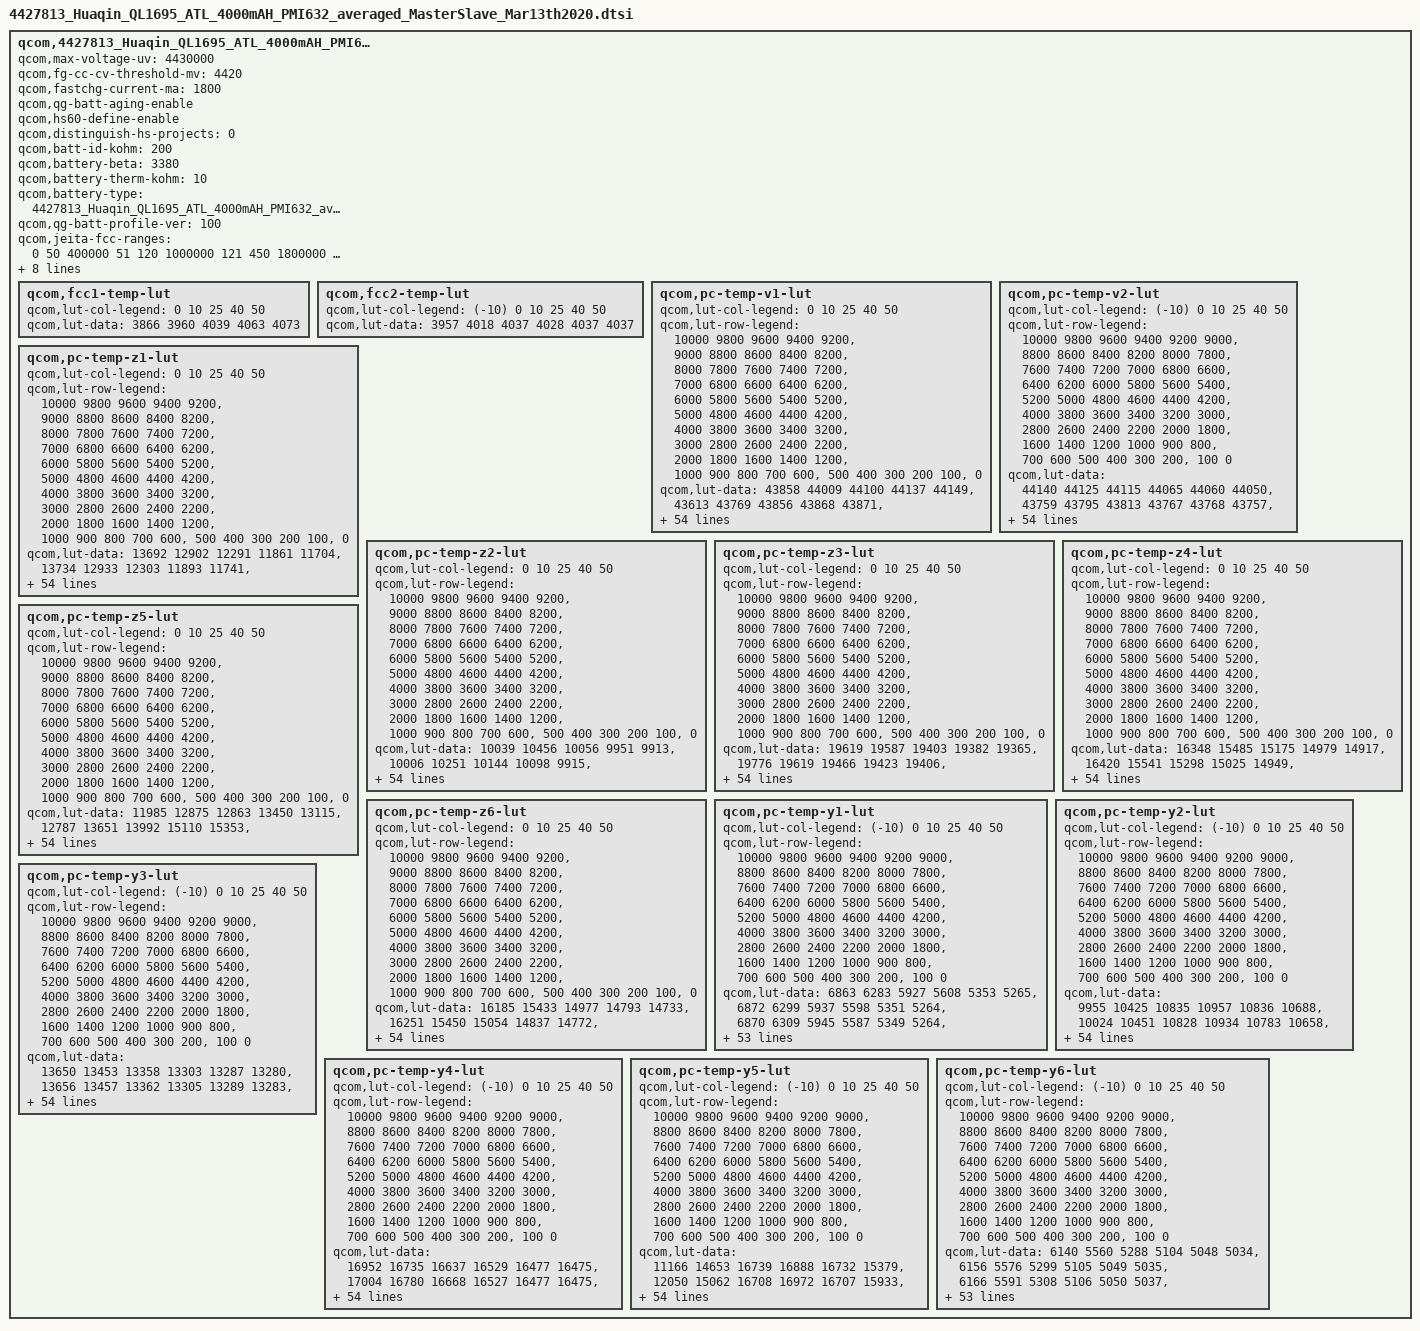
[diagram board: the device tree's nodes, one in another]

qcom,4427813_Huaqin_QL1695_ATL_4000mAH_PMI632 {
    /* 4427813_Huaqin_QL1695_ATL_4000mAH_PMI632_averaged_MasterSlave_Mar13th2020 */
    qcom,max-voltage-uv = <4430000>;
	qcom,fg-cc-cv-threshold-mv = <4420>;
	/* HS60 add for ZQL1693-60 Encrease FCC to 1800mA to trigger TA(5V/1.55A) more ICL by gaochao at 2019/11/05 start */
	qcom,fastchg-current-ma = <1800>;
	/* HS60 add for ZQL1693-60 Encrease FCC to 1800mA to trigger TA(5V/1.55A) more ICL by gaochao at 2019/11/05 end */
	/* HS60 add for SR-ZQL1695-01-357 Import battery aging by gaochao at 2019/08/29 start */
	qcom,qg-batt-aging-enable;
	/* HS60 add for SR-ZQL1695-01-357 Import battery aging by gaochao at 2019/08/29 end */
	/* HS70 add for HS70-135 Distinguish HS60 and HS70 charging by gaochao at 2019/10/03 start */
	qcom,hs60-define-enable;
	/* HS70 add for HS70-135 Distinguish HS60 and HS70 charging by gaochao at 2019/10/03 end */
	/* HS50 add for SR-QL3095-01-67 Distinguish HS60, HS70 and HS50 charging by wenyaqi at 2020/8/3 start */
	qcom,distinguish-hs-projects = <0>;
	/* HS50 add for SR-QL3095-01-67 Distinguish HS60, HS70 and HS50 charging by wenyaqi at 2020/8/3 end */
	qcom,batt-id-kohm = <200>;
	qcom,battery-beta = <3380>;
    qcom,battery-therm-kohm = <10>;
    qcom,battery-type = "4427813_Huaqin_QL1695_ATL_4000mAH_PMI632_averaged_MasterSlave_Mar13th2020";
    qcom,qg-batt-profile-ver = <100>;
	/*HS60 add for ZQL1693-50 by wangzikang at 2019/09/26 start*/
	/*HS60 add for ZQL1693-58 by wangzikang at 2019/10/18 start*/
	/* HS60 add for ZQL1693-60 Encrease FCC to 1800mA to trigger TA(5V/1.55A) more ICL by gaochao at 2019/11/05 start */
	qcom,jeita-fcc-ranges = <0   50  400000
				 51   120   1000000
				 121 450  1800000
				 451 500  1800000>;
	/* HS60 add for ZQL1693-60 Encrease FCC to 1800mA to trigger TA(5V/1.55A) more ICL by gaochao at 2019/11/05 end */
	/*HS60 add for ZQL1693-58 by wangzikang at 2019/10/18 end*/
	qcom,jeita-fv-ranges =  <0   50  4430000
				 51   120  4430000
				 121 450  4430000
				 451 500  4200000>;
	/*HS60 add for ZQL1693-50 by wangzikang at 2019/09/26 end*/
	/* HS60 add for SR-ZQL1695-01-357 Import battery aging by gaochao at 2019/08/29 start */
	qcom,vfloat-ranges = <0 299 4430000
	                      300 399 4410000
                              400 699 4390000
                              700 999 4370000
                              1000 9999 4320000>;

	qcom,vbat-rechg-ranges = <0 299 4360000
                                  300 399 4340000
                                  400 699 4320000
                                  700 999 4300000
                                  1000 9999 4250000>;
	/* HS60 add for SR-ZQL1695-01-357 Import battery aging by gaochao at 2019/08/29 end */

	/* COOL = 15 DegC, WARM = 45 DegC */
	qcom,jeita-soft-thresholds = <0x2554 0xFDC>;
	/* COLD = 0 DegC, HOT = 55 DegC */
	/*HS60 add for ZQL1693-50 by wangzikang at 2019/09/26 start*/
	qcom,jeita-hard-thresholds = <0x36B9 0xDBF>;//0xBEF -->0xDBF
	/*HS60 add for ZQL1693-50 by wangzikang at 2019/09/26 end*/
	qcom,fcc1-temp-lut {
		qcom,lut-col-legend = <0 10 25 40 50>;
		qcom,lut-data = <3866 3960 4039 4063 4073>;
	};

	qcom,fcc2-temp-lut {
		qcom,lut-col-legend = <(-10) 0 10 25 40 50>;
		qcom,lut-data = <3957 4018 4037 4028 4037 4037>;
	};

	qcom,pc-temp-v1-lut {
		qcom,lut-col-legend = <0 10 25 40 50>;
		qcom,lut-row-legend = <10000 9800 9600 9400 9200>,
			<9000 8800 8600 8400 8200>,
			<8000 7800 7600 7400 7200>,
			<7000 6800 6600 6400 6200>,
			<6000 5800 5600 5400 5200>,
			<5000 4800 4600 4400 4200>,
			<4000 3800 3600 3400 3200>,
			<3000 2800 2600 2400 2200>,
			<2000 1800 1600 1400 1200>,
			<1000 900 800 700 600>,
			<500 400 300 200 100>,
			<0>;
		qcom,lut-data = <43858 44009 44100 44137 44149>,
			<43613 43769 43856 43868 43871>,
			<43372 43531 43626 43639 43640>,
			<43133 43294 43396 43422 43424>,
			<42894 43060 43162 43193 43198>,
			<42654 42821 42925 42961 42970>,
			<42418 42579 42689 42727 42739>,
			<42183 42339 42450 42490 42503>,
			<41951 42104 42213 42253 42268>,
			<41725 41873 41976 42016 42032>,
			<41505 41646 41742 41781 41798>,
			<41290 41424 41513 41552 41568>,
			<41083 41206 41289 41329 41343>,
			<40885 41000 41073 41112 41124>,
			<40686 40799 40867 40899 40910>,
			<40482 40603 40669 40692 40702>,
			<40286 40406 40475 40495 40504>,
			<40116 40220 40287 40307 40317>,
			<39964 40054 40109 40127 40137>,
			<39815 39901 39954 39968 39974>,
			<39664 39739 39794 39810 39814>,
			<39513 39569 39577 39606 39614>,
			<39357 39386 39308 39335 39347>,
			<39192 39152 39092 39109 39118>,
			<39025 38882 38935 38962 38975>,
			<38850 38715 38808 38843 38860>,
			<38675 38634 38708 38736 38747>,
			<38559 38572 38627 38642 38638>,
			<38489 38506 38550 38552 38539>,
			<38434 38443 38475 38460 38447>,
			<38384 38384 38405 38374 38364>,
			<38338 38328 38337 38301 38289>,
			<38299 38277 38274 38237 38221>,
			<38266 38230 38217 38175 38156>,
			<38236 38188 38168 38115 38094>,
			<38206 38149 38122 38058 38033>,
			<38180 38117 38077 38005 37969>,
			<38145 38082 38032 37954 37904>,
			<38090 38026 37971 37888 37825>,
			<38009 37936 37880 37793 37724>,
			<37912 37832 37775 37682 37610>,
			<37785 37713 37661 37570 37495>,
			<37640 37574 37530 37443 37367>,
			<37473 37404 37359 37283 37199>,
			<37320 37249 37203 37135 37061>,
			<37207 37140 37097 37040 36983>,
			<37179 37103 37063 37010 36952>,
			<37143 37083 37043 36989 36934>,
			<37110 37059 37022 36971 36913>,
			<37070 37020 36983 36922 36853>,
			<36948 36834 36764 36685 36589>,
			<36547 36397 36326 36246 36147>,
			<35984 35804 35739 35667 35566>,
			<35209 34974 34941 34882 34774>,
			<33857 33573 33687 33661 33540>,
			<30000 30000 30000 30000 30000>;
	};

	qcom,pc-temp-v2-lut {
		qcom,lut-col-legend = <(-10) 0 10 25 40 50>;
		qcom,lut-row-legend = <10000 9800 9600 9400 9200 9000>,
			<8800 8600 8400 8200 8000 7800>,
			<7600 7400 7200 7000 6800 6600>,
			<6400 6200 6000 5800 5600 5400>,
			<5200 5000 4800 4600 4400 4200>,
			<4000 3800 3600 3400 3200 3000>,
			<2800 2600 2400 2200 2000 1800>,
			<1600 1400 1200 1000 900 800>,
			<700 600 500 400 300 200>,
			<100 0>;
		qcom,lut-data = <44140 44125 44115 44065 44060 44050>,
			<43759 43795 43813 43767 43768 43757>,
			<43421 43494 43532 43489 43495 43485>,
			<43137 43229 43275 43234 43243 43235>,
			<42901 42997 43041 43001 43013 43009>,
			<42670 42767 42809 42770 42784 42783>,
			<42416 42524 42568 42531 42546 42547>,
			<42159 42279 42327 42290 42307 42309>,
			<41917 42037 42085 42052 42071 42072>,
			<41687 41798 41843 41816 41835 41835>,
			<41470 41560 41607 41584 41604 41603>,
			<41279 41306 41376 41356 41379 41377>,
			<41098 41064 41151 41133 41158 41155>,
			<40890 40889 40938 40919 40942 40940>,
			<40648 40761 40731 40710 40730 40730>,
			<40384 40604 40532 40509 40527 40528>,
			<40083 40335 40345 40313 40331 40331>,
			<39760 40023 40156 40126 40144 40143>,
			<39496 39774 39944 39955 39969 39967>,
			<39289 39562 39712 39801 39804 39801>,
			<39103 39358 39486 39623 39624 39623>,
			<38910 39152 39266 39382 39410 39417>,
			<38724 38956 39059 39132 39191 39206>,
			<38567 38781 38877 38934 38992 39007>,
			<38430 38621 38714 38762 38804 38815>,
			<38317 38465 38570 38617 38652 38659>,
			<38237 38296 38444 38496 38533 38537>,
			<38175 38149 38330 38391 38430 38432>,
			<38117 38066 38221 38294 38334 38337>,
			<38059 38010 38117 38204 38244 38250>,
			<38003 37963 38026 38122 38165 38170>,
			<37947 37920 37940 38047 38095 38098>,
			<37892 37880 37871 37977 38028 38026>,
			<37833 37836 37827 37913 37959 37955>,
			<37772 37791 37796 37856 37888 37881>,
			<37708 37741 37759 37794 37811 37797>,
			<37642 37685 37721 37729 37723 37696>,
			<37573 37624 37677 37659 37633 37592>,
			<37499 37555 37620 37586 37545 37500>,
			<37415 37477 37549 37509 37457 37410>,
			<37325 37388 37461 37422 37366 37319>,
			<37237 37284 37341 37322 37273 37226>,
			<37150 37164 37197 37201 37154 37105>,
			<37070 37018 37022 37050 37002 36947>,
			<36997 36876 36866 36923 36901 36852>,
			<36921 36773 36774 36860 36844 36799>,
			<36874 36731 36741 36842 36834 36791>,
			<36821 36699 36707 36826 36822 36776>,
			<36770 36665 36662 36797 36797 36749>,
			<36716 36613 36582 36728 36728 36663>,
			<36649 36482 36371 36478 36441 36342>,
			<36511 36111 35921 35997 35956 35844>,
			<36214 35450 35289 35362 35314 35193>,
			<35642 34491 34392 34507 34436 34303>,
			<34774 33039 32911 33173 33160 33016>,
			<33584 30425 28032 27670 28469 28287>;
	};

	qcom,pc-temp-z1-lut {
		qcom,lut-col-legend = <0 10 25 40 50>;
		qcom,lut-row-legend = <10000 9800 9600 9400 9200>,
			<9000 8800 8600 8400 8200>,
			<8000 7800 7600 7400 7200>,
			<7000 6800 6600 6400 6200>,
			<6000 5800 5600 5400 5200>,
			<5000 4800 4600 4400 4200>,
			<4000 3800 3600 3400 3200>,
			<3000 2800 2600 2400 2200>,
			<2000 1800 1600 1400 1200>,
			<1000 900 800 700 600>,
			<500 400 300 200 100>,
			<0>;
		qcom,lut-data = <13692 12902 12291 11861 11704>,
			<13734 12933 12303 11893 11741>,
			<13728 12947 12302 11892 11742>,
			<13718 12942 12297 11887 11743>,
			<13712 12930 12284 11881 11742>,
			<13703 12916 12264 11874 11739>,
			<13692 12898 12250 11868 11736>,
			<13661 12879 12237 11862 11735>,
			<13612 12864 12227 11857 11735>,
			<13588 12849 12217 11855 11734>,
			<13588 12835 12210 11854 11732>,
			<13590 12816 12209 11853 11731>,
			<13581 12803 12212 11851 11731>,
			<13563 12798 12214 11850 11730>,
			<13544 12795 12212 11850 11731>,
			<13526 12795 12209 11851 11731>,
			<13509 12795 12209 11851 11732>,
			<13498 12795 12212 11853 11733>,
			<13488 12795 12214 11854 11735>,
			<13482 12794 12217 11856 11737>,
			<13477 12795 12220 11857 11739>,
			<13471 12797 12222 11858 11741>,
			<13474 12800 12225 11859 11741>,
			<13487 12804 12228 11860 11742>,
			<13498 12811 12234 11863 11744>,
			<13498 12817 12240 11867 11746>,
			<13496 12823 12243 11870 11749>,
			<13496 12827 12245 11873 11753>,
			<13512 12827 12248 11876 11757>,
			<13531 12829 12255 11882 11760>,
			<13537 12829 12264 11888 11763>,
			<13540 12828 12269 11894 11766>,
			<13541 12828 12273 11899 11771>,
			<13542 12835 12279 11904 11775>,
			<13545 12854 12288 11908 11781>,
			<13547 12867 12296 11913 11787>,
			<13551 12875 12304 11917 11791>,
			<13556 12881 12310 11923 11794>,
			<13588 12885 12317 11927 11797>,
			<13643 12891 12325 11932 11801>,
			<13665 12900 12331 11936 11804>,
			<13670 12914 12335 11940 11807>,
			<13675 12927 12340 11945 11810>,
			<13673 12938 12354 11951 11814>,
			<13697 12943 12374 11958 11817>,
			<13688 12937 12386 11961 11818>,
			<13677 12947 12374 11961 11817>,
			<13683 12926 12387 11962 11818>,
			<13694 12957 12391 11964 11820>,
			<13686 12940 12384 11968 11824>,
			<13678 12950 12413 11979 11829>,
			<13720 12960 12413 11987 11837>,
			<13713 13001 12435 11999 11849>,
			<13772 13045 12469 12018 11865>,
			<13772 13045 12469 12018 11865>,
			<13772 13045 12469 12018 11865>;
	};

	qcom,pc-temp-z2-lut {
		qcom,lut-col-legend = <0 10 25 40 50>;
		qcom,lut-row-legend = <10000 9800 9600 9400 9200>,
			<9000 8800 8600 8400 8200>,
			<8000 7800 7600 7400 7200>,
			<7000 6800 6600 6400 6200>,
			<6000 5800 5600 5400 5200>,
			<5000 4800 4600 4400 4200>,
			<4000 3800 3600 3400 3200>,
			<3000 2800 2600 2400 2200>,
			<2000 1800 1600 1400 1200>,
			<1000 900 800 700 600>,
			<500 400 300 200 100>,
			<0>;
		qcom,lut-data = <10039 10456 10056 9951 9913>,
			<10006 10251 10144 10098 9915>,
			<9996 10139 10175 10113 9989>,
			<9989 10113 10185 10116 10055>,
			<9980 10088 10171 10108 10056>,
			<9967 10063 10143 10083 10027>,
			<9956 10036 10112 10061 9999>,
			<9948 10015 10074 10028 9978>,
			<9940 10004 10049 10001 9960>,
			<9933 9996 10039 10002 9946>,
			<9923 9993 10033 10007 9935>,
			<9915 9992 10036 10006 9927>,
			<9913 9992 10054 9991 9919>,
			<9912 10002 10080 9978 9915>,
			<9911 10028 10236 9987 9916>,
			<9912 10049 10405 10006 9918>,
			<9914 10066 10367 10008 9917>,
			<9941 10080 10196 9990 9908>,
			<10026 10091 10125 9974 9903>,
			<10076 10101 10131 9963 9910>,
			<10050 10110 10140 9955 9924>,
			<10011 10118 10186 9998 9975>,
			<10007 10126 10298 10227 10190>,
			<10019 10138 10340 10365 10332>,
			<10031 10151 10241 10219 10219>,
			<10040 10155 10137 10016 10041>,
			<10049 10141 10136 9991 10058>,
			<10055 10127 10154 10012 10292>,
			<10059 10129 10170 10042 10425>,
			<10063 10138 10185 10115 10327>,
			<10065 10145 10197 10187 10162>,
			<10068 10149 10201 10178 10036>,
			<10070 10153 10203 10124 9919>,
			<10074 10156 10202 10092 9876>,
			<10079 10160 10194 10081 9890>,
			<10085 10164 10188 10074 9913>,
			<10090 10169 10199 10072 9944>,
			<10096 10175 10227 10071 9985>,
			<10105 10186 10252 10078 10020>,
			<10117 10203 10277 10144 10047>,
			<10127 10214 10291 10203 10070>,
			<10135 10217 10287 10194 10093>,
			<10147 10221 10281 10169 10115>,
			<10172 10231 10285 10149 10135>,
			<10393 10323 10303 10145 10113>,
			<10452 10393 10333 10125 10054>,
			<10487 10378 10338 10120 10068>,
			<10390 10446 10318 10127 10074>,
			<10350 10623 10290 10134 10077>,
			<10332 10710 10321 10200 10132>,
			<10232 10578 10395 10149 10071>,
			<10233 10614 10371 10026 9897>,
			<10017 10522 10316 9984 9845>,
			<9881 10277 10318 9943 9816>,
			<9881 10277 10318 9943 9816>,
			<9881 10277 10318 9943 9816>;
	};

	qcom,pc-temp-z3-lut {
		qcom,lut-col-legend = <0 10 25 40 50>;
		qcom,lut-row-legend = <10000 9800 9600 9400 9200>,
			<9000 8800 8600 8400 8200>,
			<8000 7800 7600 7400 7200>,
			<7000 6800 6600 6400 6200>,
			<6000 5800 5600 5400 5200>,
			<5000 4800 4600 4400 4200>,
			<4000 3800 3600 3400 3200>,
			<3000 2800 2600 2400 2200>,
			<2000 1800 1600 1400 1200>,
			<1000 900 800 700 600>,
			<500 400 300 200 100>,
			<0>;
		qcom,lut-data = <19619 19587 19403 19382 19365>,
			<19776 19619 19466 19423 19406>,
			<19859 19644 19500 19440 19425>,
			<19910 19666 19522 19450 19435>,
			<19923 19687 19537 19464 19445>,
			<19929 19694 19547 19478 19454>,
			<19931 19697 19547 19482 19458>,
			<19930 19698 19539 19481 19459>,
			<19926 19693 19531 19479 19459>,
			<19923 19681 19527 19476 19457>,
			<19921 19672 19523 19471 19452>,
			<19918 19666 19517 19465 19446>,
			<19913 19660 19509 19455 19440>,
			<19905 19650 19504 19445 19434>,
			<19900 19636 19507 19441 19431>,
			<19897 19627 19511 19437 19426>,
			<19895 19619 19503 19433 19422>,
			<19888 19614 19483 19428 19416>,
			<19872 19609 19471 19422 19408>,
			<19861 19605 19466 19412 19401>,
			<19847 19603 19463 19402 19394>,
			<19829 19606 19472 19404 19395>,
			<19828 19609 19503 19426 19407>,
			<19832 19618 19515 19439 19416>,
			<19836 19633 19494 19418 19397>,
			<19840 19638 19469 19389 19368>,
			<19845 19626 19461 19384 19374>,
			<19846 19611 19457 19383 19423>,
			<19837 19606 19456 19384 19451>,
			<19825 19604 19463 19410 19450>,
			<19817 19603 19472 19440 19449>,
			<19811 19607 19481 19442 19444>,
			<19806 19611 19492 19437 19431>,
			<19800 19611 19494 19432 19418>,
			<19793 19610 19490 19427 19406>,
			<19786 19609 19483 19421 19396>,
			<19778 19604 19477 19411 19388>,
			<19770 19596 19471 19398 19382>,
			<19762 19590 19466 19394 19379>,
			<19753 19585 19463 19396 19378>,
			<19743 19579 19459 19397 19377>,
			<19732 19572 19452 19395 19379>,
			<19718 19563 19445 19392 19385>,
			<19698 19552 19441 19392 19394>,
			<19588 19510 19429 19389 19394>,
			<19513 19482 19415 19376 19372>,
			<19332 19483 19417 19371 19366>,
			<19318 19442 19410 19369 19353>,
			<19312 19382 19403 19361 19348>,
			<19304 19348 19382 19351 19342>,
			<19287 19418 19392 19369 19368>,
			<19318 19352 19398 19398 19390>,
			<19329 19346 19408 19401 19391>,
			<19350 19420 19374 19389 19383>,
			<19350 19420 19374 19389 19383>,
			<19350 19420 19374 19389 19383>;
	};

	qcom,pc-temp-z4-lut {
		qcom,lut-col-legend = <0 10 25 40 50>;
		qcom,lut-row-legend = <10000 9800 9600 9400 9200>,
			<9000 8800 8600 8400 8200>,
			<8000 7800 7600 7400 7200>,
			<7000 6800 6600 6400 6200>,
			<6000 5800 5600 5400 5200>,
			<5000 4800 4600 4400 4200>,
			<4000 3800 3600 3400 3200>,
			<3000 2800 2600 2400 2200>,
			<2000 1800 1600 1400 1200>,
			<1000 900 800 700 600>,
			<500 400 300 200 100>,
			<0>;
		qcom,lut-data = <16348 15485 15175 14979 14917>,
			<16420 15541 15298 15025 14949>,
			<16225 15527 15211 14994 14932>,
			<15923 15417 15115 14946 14901>,
			<15717 15259 15043 14908 14874>,
			<15561 15149 14979 14870 14848>,
			<15430 15069 14935 14840 14823>,
			<15319 15007 14902 14817 14800>,
			<15225 14961 14872 14796 14780>,
			<15151 14925 14842 14776 14765>,
			<15091 14893 14815 14758 14753>,
			<15040 14865 14797 14749 14745>,
			<14994 14842 14784 14746 14740>,
			<14953 14821 14771 14742 14735>,
			<14923 14803 14746 14735 14730>,
			<14903 14796 14723 14726 14724>,
			<14886 14795 14725 14720 14719>,
			<14858 14793 14741 14714 14715>,
			<14819 14784 14746 14711 14710>,
			<14798 14766 14738 14708 14704>,
			<14796 14760 14732 14706 14698>,
			<14797 14764 14746 14717 14705>,
			<14801 14774 14797 14775 14770>,
			<14810 14813 14845 14830 14829>,
			<14823 14896 14889 14866 14857>,
			<14855 14928 14918 14891 14876>,
			<14902 14917 14915 14890 14865>,
			<14918 14900 14899 14874 14796>,
			<14913 14884 14880 14850 14745>,
			<14904 14865 14855 14808 14730>,
			<14894 14847 14828 14763 14720>,
			<14881 14830 14804 14744 14715>,
			<14867 14815 14780 14731 14711>,
			<14854 14803 14768 14725 14708>,
			<14840 14793 14761 14721 14706>,
			<14826 14785 14756 14719 14705>,
			<14811 14777 14755 14720 14705>,
			<14798 14771 14754 14723 14706>,
			<14786 14768 14755 14727 14709>,
			<14776 14767 14761 14738 14726>,
			<14767 14764 14767 14747 14742>,
			<14759 14753 14760 14744 14735>,
			<14749 14738 14746 14738 14723>,
			<14733 14730 14739 14736 14723>,
			<14731 14710 14720 14722 14713>,
			<14784 14694 14694 14702 14694>,
			<14982 14686 14682 14698 14692>,
			<14992 14715 14669 14682 14685>,
			<14993 14773 14659 14662 14660>,
			<14993 14806 14669 14656 14649>,
			<14999 14730 14682 14679 14677>,
			<14987 14820 14692 14672 14681>,
			<14997 14836 14685 14675 14685>,
			<15004 14772 14726 14690 14695>,
			<15004 14772 14726 14690 14695>,
			<15004 14772 14726 14690 14695>;
	};

	qcom,pc-temp-z5-lut {
		qcom,lut-col-legend = <0 10 25 40 50>;
		qcom,lut-row-legend = <10000 9800 9600 9400 9200>,
			<9000 8800 8600 8400 8200>,
			<8000 7800 7600 7400 7200>,
			<7000 6800 6600 6400 6200>,
			<6000 5800 5600 5400 5200>,
			<5000 4800 4600 4400 4200>,
			<4000 3800 3600 3400 3200>,
			<3000 2800 2600 2400 2200>,
			<2000 1800 1600 1400 1200>,
			<1000 900 800 700 600>,
			<500 400 300 200 100>,
			<0>;
		qcom,lut-data = <11985 12875 12863 13450 13115>,
			<12787 13651 13992 15110 15353>,
			<13321 14308 14821 15907 16584>,
			<13734 14829 15526 16397 17319>,
			<14055 15316 16244 17218 18200>,
			<14304 15837 16808 18219 19092>,
			<14581 16439 16917 18847 19851>,
			<14967 16954 16928 19132 20448>,
			<15425 17255 16952 19419 20995>,
			<15907 17492 17324 20161 21630>,
			<16430 17853 17996 21216 22322>,
			<17013 18454 18581 21467 22801>,
			<17648 19134 19190 20950 23087>,
			<18355 19832 19824 20520 23219>,
			<19206 20554 22072 20953 23705>,
			<20453 21029 24367 21968 24831>,
			<21793 21281 23849 22741 25182>,
			<22891 21556 21767 23452 25176>,
			<23967 22186 21133 23815 25336>,
			<24369 23287 21678 23228 25641>,
			<24902 24640 22644 22264 25962>,
			<26450 27193 28150 23635 26963>,
			<28883 30423 41885 31659 30606>,
			<34286 34008 47128 36498 32995>,
			<39289 37953 36459 29285 26898>,
			<41841 39036 24141 18798 17288>,
			<43825 33690 20979 16230 16252>,
			<44163 27545 19357 15422 19746>,
			<40846 25984 18973 15216 22772>,
			<36741 25227 19431 17430 24501>,
			<35070 25042 20309 20562 25682>,
			<34061 26185 22258 21936 25751>,
			<33378 28099 25677 22762 25181>,
			<32866 30105 28127 23737 24653>,
			<32485 32530 29936 25447 24271>,
			<32279 33733 30969 26757 24031>,
			<32176 33887 31078 26141 24142>,
			<32201 33903 31126 24342 24444>,
			<32973 33934 31058 23727 24298>,
			<34297 34002 30231 24029 23402>,
			<34602 34024 28943 24303 22525>,
			<33646 32782 26704 22994 22173>,
			<32851 31034 24701 20907 21991>,
			<32442 29896 24849 21132 24682>,
			<25301 27522 25112 21799 25912>,
			<20249 25081 24904 20109 20183>,
			<11744 25359 26465 19138 18759>,
			<11552 17571 25341 20074 17257>,
			<11474 13874 24857 20953 19455>,
			<11404 12625 19456 20349 20779>,
			<11342 15875 19827 20427 21865>,
			<11555 12656 17876 22143 20930>,
			<11523 12383 18798 20782 18809>,
			<11935 17107 14380 16521 15848>,
			<11935 17107 14380 16521 15848>,
			<11935 17107 14380 16521 15848>;
	};

	qcom,pc-temp-z6-lut {
		qcom,lut-col-legend = <0 10 25 40 50>;
		qcom,lut-row-legend = <10000 9800 9600 9400 9200>,
			<9000 8800 8600 8400 8200>,
			<8000 7800 7600 7400 7200>,
			<7000 6800 6600 6400 6200>,
			<6000 5800 5600 5400 5200>,
			<5000 4800 4600 4400 4200>,
			<4000 3800 3600 3400 3200>,
			<3000 2800 2600 2400 2200>,
			<2000 1800 1600 1400 1200>,
			<1000 900 800 700 600>,
			<500 400 300 200 100>,
			<0>;
		qcom,lut-data = <16185 15433 14977 14793 14733>,
			<16251 15450 15054 14837 14772>,
			<16176 15448 15033 14830 14771>,
			<16045 15407 15007 14819 14769>,
			<15946 15331 14982 14809 14765>,
			<15862 15275 14955 14799 14757>,
			<15787 15233 14932 14789 14750>,
			<15719 15196 14911 14778 14741>,
			<15659 15164 14892 14768 14733>,
			<15613 15136 14875 14757 14724>,
			<15579 15113 14860 14747 14716>,
			<15549 15093 14847 14738 14709>,
			<15517 15075 14837 14731 14703>,
			<15487 15058 14828 14724 14698>,
			<15464 15042 14820 14718 14693>,
			<15448 15033 14813 14712 14688>,
			<15434 15028 14808 14706 14683>,
			<15414 15023 14803 14701 14677>,
			<15387 15016 14799 14696 14671>,
			<15369 15007 14794 14689 14664>,
			<15362 15004 14790 14683 14658>,
			<15356 15007 14802 14690 14662>,
			<15356 15015 14843 14732 14700>,
			<15363 15038 14866 14757 14727>,
			<15374 15083 14873 14757 14725>,
			<15393 15100 14876 14757 14722>,
			<15419 15091 14874 14755 14720>,
			<15428 15078 14865 14747 14717>,
			<15423 15069 14857 14741 14713>,
			<15415 15060 14851 14737 14708>,
			<15407 15054 14846 14734 14703>,
			<15400 15051 14842 14729 14697>,
			<15392 15048 14839 14722 14690>,
			<15386 15045 14835 14716 14683>,
			<15380 15042 14831 14713 14676>,
			<15374 15039 14827 14709 14670>,
			<15366 15035 14824 14705 14667>,
			<15361 15032 14822 14699 14664>,
			<15361 15032 14821 14698 14663>,
			<15362 15033 14824 14704 14669>,
			<15362 15033 14826 14709 14675>,
			<15363 15030 14822 14707 14674>,
			<15363 15025 14814 14704 14672>,
			<15358 15021 14813 14704 14677>,
			<15322 15002 14803 14697 14674>,
			<15311 14984 14787 14682 14654>,
			<15303 14982 14784 14678 14650>,
			<15300 14975 14775 14670 14640>,
			<15300 14970 14768 14657 14627>,
			<15301 14969 14764 14649 14618>,
			<15309 14981 14778 14670 14645>,
			<15326 14993 14790 14686 14662>,
			<15350 15006 14797 14692 14668>,
			<15385 15033 14804 14697 14673>,
			<15385 15033 14804 14697 14673>,
			<15385 15033 14804 14697 14673>;
	};

	qcom,pc-temp-y1-lut {
		qcom,lut-col-legend = <(-10) 0 10 25 40 50>;
		qcom,lut-row-legend = <10000 9800 9600 9400 9200 9000>,
			<8800 8600 8400 8200 8000 7800>,
			<7600 7400 7200 7000 6800 6600>,
			<6400 6200 6000 5800 5600 5400>,
			<5200 5000 4800 4600 4400 4200>,
			<4000 3800 3600 3400 3200 3000>,
			<2800 2600 2400 2200 2000 1800>,
			<1600 1400 1200 1000 900 800>,
			<700 600 500 400 300 200>,
			<100 0>;
		qcom,lut-data = <6863 6283 5927 5608 5353 5265>,
			<6872 6299 5937 5598 5351 5264>,
			<6870 6309 5945 5587 5349 5264>,
			<6863 6313 5949 5577 5347 5263>,
			<6855 6314 5952 5570 5345 5263>,
			<6851 6312 5952 5566 5343 5262>,
			<6847 6302 5946 5566 5341 5262>,
			<6841 6290 5940 5567 5339 5262>,
			<6843 6291 5939 5566 5338 5261>,
			<6848 6301 5944 5563 5337 5259>,
			<6851 6308 5946 5561 5337 5258>,
			<6853 6309 5940 5559 5335 5258>,
			<6854 6309 5932 5558 5334 5258>,
			<6855 6312 5931 5558 5334 5258>,
			<6854 6324 5929 5558 5334 5259>,
			<6852 6331 5929 5558 5334 5260>,
			<6851 6324 5929 5561 5335 5262>,
			<6846 6315 5930 5564 5336 5263>,
			<6843 6315 5933 5564 5337 5263>,
			<6836 6319 5939 5562 5337 5263>,
			<6827 6321 5943 5561 5338 5263>,
			<6826 6329 5944 5565 5339 5263>,
			<6833 6339 5944 5571 5341 5264>,
			<6837 6338 5945 5577 5343 5266>,
			<6842 6325 5945 5584 5346 5268>,
			<6846 6318 5945 5588 5348 5271>,
			<6841 6319 5945 5589 5351 5272>,
			<6831 6320 5946 5589 5354 5273>,
			<6833 6320 5951 5592 5357 5275>,
			<6850 6320 5964 5598 5360 5279>,
			<6866 6321 5968 5604 5363 5282>,
			<6864 6323 5958 5611 5366 5284>,
			<6854 6326 5949 5616 5369 5286>,
			<6843 6324 5954 5620 5372 5288>,
			<6833 6317 5967 5624 5376 5290>,
			<6823 6314 5975 5626 5378 5291>,
			<6823 6318 5982 5628 5380 5292>,
			<6826 6325 5986 5630 5381 5293>,
			<6826 6328 5985 5635 5382 5295>,
			<6812 6332 5984 5643 5384 5296>,
			<6796 6332 5983 5649 5385 5297>,
			<6801 6322 5980 5653 5386 5298>,
			<6830 6313 5980 5658 5389 5299>,
			<6835 6309 5987 5665 5394 5302>,
			<6827 6343 5984 5680 5395 5306>,
			<6842 6354 5994 5678 5401 5308>,
			<6887 6362 6005 5688 5401 5308>,
			<6898 6373 6010 5685 5400 5309>,
			<6876 6366 6014 5687 5401 5308>,
			<6926 6389 6012 5690 5400 5310>,
			<6973 6411 6033 5683 5402 5311>,
			<7052 6471 6029 5699 5411 5315>,
			<7184 6599 6094 5722 5417 5322>,
			<7323 6836 6160 5746 5426 5334>,
			<7323 6836 6160 5746 5426 5334>,
			<7323 6836 6160 5746 5426 5334>;
	};

	qcom,pc-temp-y2-lut {
		qcom,lut-col-legend = <(-10) 0 10 25 40 50>;
		qcom,lut-row-legend = <10000 9800 9600 9400 9200 9000>,
			<8800 8600 8400 8200 8000 7800>,
			<7600 7400 7200 7000 6800 6600>,
			<6400 6200 6000 5800 5600 5400>,
			<5200 5000 4800 4600 4400 4200>,
			<4000 3800 3600 3400 3200 3000>,
			<2800 2600 2400 2200 2000 1800>,
			<1600 1400 1200 1000 900 800>,
			<700 600 500 400 300 200>,
			<100 0>;
		qcom,lut-data = <9955 10425 10835 10957 10836 10688>,
			<10024 10451 10828 10934 10783 10658>,
			<10095 10485 10818 10910 10731 10629>,
			<10164 10518 10806 10884 10682 10602>,
			<10222 10547 10793 10858 10639 10578>,
			<10263 10562 10780 10832 10606 10558>,
			<10284 10569 10765 10804 10578 10543>,
			<10300 10574 10751 10778 10558 10531>,
			<10349 10568 10742 10762 10552 10517>,
			<10512 10538 10734 10749 10555 10501>,
			<10630 10520 10731 10744 10560 10492>,
			<10590 10610 10732 10750 10577 10494>,
			<10508 10735 10737 10760 10600 10498>,
			<10495 10745 10752 10776 10613 10497>,
			<10578 10705 10801 10810 10624 10493>,
			<10649 10682 10849 10850 10640 10492>,
			<10407 10724 10892 10896 10668 10513>,
			<9877 10789 10928 10948 10709 10552>,
			<9697 10820 10948 11004 10780 10600>,
			<9692 10840 10963 11068 10892 10669>,
			<9688 10849 10972 11092 10953 10736>,
			<9684 10852 10978 11064 10972 10811>,
			<9680 10853 10981 11023 10976 10864>,
			<9677 10834 10980 11003 10929 10845>,
			<9674 10764 10977 10987 10820 10780>,
			<9672 10728 10976 10983 10780 10755>,
			<9670 10728 10985 11000 10819 10773>,
			<9669 10727 10994 11029 10870 10801>,
			<9668 10719 10981 11060 10898 10834>,
			<9667 10680 10943 11096 10920 10875>,
			<9666 10605 10925 11113 10950 10900>,
			<9665 10221 10923 11114 11006 10910>,
			<9665 9792 10921 11113 11060 10922>,
			<9664 9714 10908 11112 11096 10992>,
			<9663 9692 10880 11111 11125 11121>,
			<9663 9681 10849 11108 11123 11149>,
			<9663 9675 10814 11093 11019 11018>,
			<9662 9671 10770 11073 10926 10885>,
			<9662 9667 10711 11049 10916 10843>,
			<9662 9664 10635 11014 10913 10816>,
			<9662 9663 10557 10986 10916 10818>,
			<9661 9661 10481 10963 10931 10870>,
			<9661 9661 10271 10929 10924 10873>,
			<9660 9660 9785 10864 10842 10768>,
			<9660 9659 9711 10811 10732 10612>,
			<9659 9658 9701 10840 10687 10549>,
			<9658 9658 9686 10814 10701 10559>,
			<9657 9657 9675 10815 10721 10576>,
			<9656 9656 9668 10830 10758 10608>,
			<9654 9655 9663 10830 10756 10588>,
			<9651 9653 9659 10781 10692 10562>,
			<9648 9650 9656 10697 10619 10507>,
			<9648 9648 9653 10618 10551 10424>,
			<9647 9647 9650 10536 10508 10335>,
			<9647 9647 9650 10536 10508 10335>,
			<9647 9647 9650 10536 10508 10335>;
	};

	qcom,pc-temp-y3-lut {
		qcom,lut-col-legend = <(-10) 0 10 25 40 50>;
		qcom,lut-row-legend = <10000 9800 9600 9400 9200 9000>,
			<8800 8600 8400 8200 8000 7800>,
			<7600 7400 7200 7000 6800 6600>,
			<6400 6200 6000 5800 5600 5400>,
			<5200 5000 4800 4600 4400 4200>,
			<4000 3800 3600 3400 3200 3000>,
			<2800 2600 2400 2200 2000 1800>,
			<1600 1400 1200 1000 900 800>,
			<700 600 500 400 300 200>,
			<100 0>;
		qcom,lut-data = <13650 13453 13358 13303 13287 13280>,
			<13656 13457 13362 13305 13289 13283>,
			<13660 13461 13366 13308 13290 13285>,
			<13662 13466 13370 13310 13291 13288>,
			<13662 13469 13373 13312 13292 13290>,
			<13661 13472 13376 13313 13293 13292>,
			<13652 13474 13379 13314 13294 13293>,
			<13635 13476 13381 13315 13295 13293>,
			<13628 13475 13382 13316 13296 13294>,
			<13626 13471 13383 13317 13296 13294>,
			<13623 13465 13383 13318 13298 13294>,
			<13593 13448 13383 13319 13301 13295>,
			<13539 13430 13383 13319 13305 13297>,
			<13525 13428 13378 13320 13306 13299>,
			<13532 13432 13365 13323 13307 13301>,
			<13539 13435 13358 13324 13308 13303>,
			<13534 13432 13363 13321 13309 13304>,
			<13522 13426 13368 13317 13310 13304>,
			<13516 13420 13367 13317 13309 13304>,
			<13513 13413 13361 13319 13307 13304>,
			<13512 13405 13356 13320 13305 13303>,
			<13513 13397 13351 13317 13302 13300>,
			<13516 13389 13347 13312 13299 13296>,
			<13516 13383 13343 13308 13295 13292>,
			<13507 13379 13340 13304 13292 13289>,
			<13497 13373 13337 13303 13290 13287>,
			<13505 13360 13335 13302 13290 13286>,
			<13534 13349 13333 13302 13289 13285>,
			<13564 13348 13333 13302 13288 13286>,
			<13591 13348 13332 13302 13287 13288>,
			<13621 13349 13331 13301 13286 13288>,
			<13655 13362 13327 13301 13288 13287>,
			<13695 13384 13323 13301 13289 13285>,
			<13736 13406 13325 13301 13289 13286>,
			<13777 13431 13331 13302 13289 13288>,
			<13817 13460 13335 13302 13289 13289>,
			<13858 13493 13338 13302 13289 13287>,
			<13897 13532 13342 13302 13289 13286>,
			<13932 13581 13346 13303 13290 13287>,
			<13961 13643 13351 13303 13291 13288>,
			<13988 13707 13356 13304 13292 13289>,
			<14016 13772 13361 13306 13292 13290>,
			<14044 13835 13369 13307 13291 13289>,
			<14085 13893 13385 13306 13286 13284>,
			<14145 13963 13414 13308 13288 13287>,
			<14227 13970 13428 13309 13293 13292>,
			<14227 14044 13454 13313 13298 13297>,
			<14329 14136 13498 13320 13303 13299>,
			<14492 14244 13567 13325 13305 13300>,
			<14774 14406 13679 13329 13304 13299>,
			<15759 14810 13847 13326 13298 13295>,
			<18505 16547 14152 13327 13299 13295>,
			<26794 24315 14655 13337 13302 13301>,
			<59432 65535 17103 13355 13313 13313>,
			<59432 65535 17103 13355 13313 13313>,
			<59432 65535 17103 13355 13313 13313>;
	};

	qcom,pc-temp-y4-lut {
		qcom,lut-col-legend = <(-10) 0 10 25 40 50>;
		qcom,lut-row-legend = <10000 9800 9600 9400 9200 9000>,
			<8800 8600 8400 8200 8000 7800>,
			<7600 7400 7200 7000 6800 6600>,
			<6400 6200 6000 5800 5600 5400>,
			<5200 5000 4800 4600 4400 4200>,
			<4000 3800 3600 3400 3200 3000>,
			<2800 2600 2400 2200 2000 1800>,
			<1600 1400 1200 1000 900 800>,
			<700 600 500 400 300 200>,
			<100 0>;
		qcom,lut-data = <16952 16735 16637 16529 16477 16475>,
			<17004 16780 16668 16527 16477 16475>,
			<17080 16849 16701 16527 16478 16475>,
			<17160 16922 16731 16526 16478 16475>,
			<17225 16981 16753 16526 16479 16474>,
			<17253 17004 16761 16526 16480 16474>,
			<17249 16998 16756 16527 16482 16474>,
			<17239 16990 16747 16529 16483 16474>,
			<17225 16989 16742 16531 16485 16474>,
			<17195 16996 16739 16534 16488 16477>,
			<17175 17006 16738 16539 16490 16480>,
			<17239 17024 16742 16545 16491 16482>,
			<17362 17052 16751 16553 16491 16484>,
			<17385 17091 16777 16562 16493 16487>,
			<17274 17152 16834 16571 16500 16489>,
			<17149 17181 16861 16584 16508 16493>,
			<17085 17095 16859 16608 16517 16499>,
			<17037 16964 16853 16637 16529 16508>,
			<16992 16905 16836 16664 16551 16523>,
			<16951 16874 16795 16690 16585 16547>,
			<16910 16842 16750 16699 16598 16556>,
			<16856 16802 16704 16650 16582 16552>,
			<16797 16760 16661 16580 16555 16543>,
			<16779 16723 16633 16545 16526 16523>,
			<16783 16687 16610 16520 16493 16487>,
			<16788 16653 16596 16512 16482 16474>,
			<16786 16610 16588 16513 16484 16477>,
			<16780 16577 16580 16514 16489 16481>,
			<16776 16577 16566 16518 16496 16486>,
			<16776 16589 16546 16523 16508 16493>,
			<16776 16606 16533 16529 16519 16502>,
			<16778 16632 16526 16536 16530 16518>,
			<16780 16661 16523 16541 16537 16531>,
			<16783 16681 16529 16542 16540 16532>,
			<16788 16697 16547 16542 16541 16533>,
			<16793 16710 16567 16542 16540 16532>,
			<16792 16722 16593 16533 16525 16518>,
			<16788 16732 16619 16524 16510 16506>,
			<16783 16740 16643 16523 16502 16505>,
			<16778 16747 16663 16523 16497 16505>,
			<16774 16749 16666 16525 16497 16506>,
			<16775 16742 16660 16536 16505 16514>,
			<16782 16730 16659 16539 16502 16510>,
			<16790 16707 16665 16533 16474 16470>,
			<16800 16693 16658 16529 16468 16460>,
			<16804 16669 16641 16512 16474 16480>,
			<16778 16683 16656 16527 16499 16516>,
			<16786 16697 16680 16549 16534 16552>,
			<16794 16720 16710 16584 16570 16589>,
			<16811 16751 16751 16620 16591 16595>,
			<16942 16778 16784 16582 16510 16502>,
			<17383 16963 16764 16564 16486 16488>,
			<18908 18900 16780 16588 16491 16489>,
			<29518 39591 17425 16638 16508 16503>,
			<29518 39591 17425 16638 16508 16503>,
			<29518 39591 17425 16638 16508 16503>;
	};

	qcom,pc-temp-y5-lut {
		qcom,lut-col-legend = <(-10) 0 10 25 40 50>;
		qcom,lut-row-legend = <10000 9800 9600 9400 9200 9000>,
			<8800 8600 8400 8200 8000 7800>,
			<7600 7400 7200 7000 6800 6600>,
			<6400 6200 6000 5800 5600 5400>,
			<5200 5000 4800 4600 4400 4200>,
			<4000 3800 3600 3400 3200 3000>,
			<2800 2600 2400 2200 2000 1800>,
			<1600 1400 1200 1000 900 800>,
			<700 600 500 400 300 200>,
			<100 0>;
		qcom,lut-data = <11166 14653 16739 16888 16732 15379>,
			<12050 15062 16708 16972 16707 15933>,
			<13408 15460 16734 16983 16601 16772>,
			<14886 15830 16803 16936 16440 17659>,
			<16131 16155 16903 16842 16248 18354>,
			<16785 16418 17022 16714 16048 18619>,
			<16910 16661 17220 16421 15749 18498>,
			<16982 16842 17409 15998 15401 18246>,
			<17276 16821 17356 15642 15152 17761>,
			<18401 16539 16980 15308 14923 16599>,
			<19227 16123 16595 14999 14837 15841>,
			<18777 15183 16338 14598 15413 15819>,
			<17873 14177 16062 14241 16151 15968>,
			<18018 14614 15546 14170 16106 16042>,
			<21567 17214 14714 14158 15565 16186>,
			<24576 19014 14386 14133 15146 16122>,
			<22206 19387 15899 13899 14797 15664>,
			<16877 19654 18114 13629 14509 15096>,
			<15180 20153 19361 14098 14401 14676>,
			<15542 20926 20279 16145 14169 14301>,
			<15873 21550 21039 18150 14176 14257>,
			<15756 21892 21809 20041 16969 16495>,
			<15330 22206 22313 21418 19995 18964>,
			<14732 22807 22311 21182 19975 19112>,
			<13326 23772 22210 20007 19114 18762>,
			<12120 24134 22184 19377 18248 18299>,
			<12113 20202 22500 19254 17422 16817>,
			<12345 15170 22961 19193 16633 15489>,
			<12552 14087 23674 19221 15907 15481>,
			<12700 13742 24838 19336 15240 15647>,
			<12844 13596 24945 19453 15106 15685>,
			<13022 13531 21222 19703 15901 15397>,
			<13242 13497 17767 20103 16838 15130>,
			<13408 13562 17865 20814 17267 15713>,
			<13498 13829 18401 21874 17624 17229>,
			<13585 14073 18541 22201 18163 18182>,
			<13786 14274 18264 21586 19238 18642>,
			<14140 14449 18023 20715 20165 19062>,
			<14300 14553 18061 19993 20532 19694>,
			<14138 14628 18152 19261 20771 20381>,
			<13827 14647 18169 18667 20762 20640>,
			<13436 14699 18060 18204 20205 20531>,
			<12921 14707 17404 17616 19205 20067>,
			<12774 14479 14933 16798 17550 18690>,
			<12831 14042 14277 16931 17018 18202>,
			<13123 13937 14548 18131 16220 16410>,
			<13055 13563 14486 17477 16653 15998>,
			<12984 13727 14275 17889 16666 15365>,
			<13261 13805 14166 17721 16248 14985>,
			<13425 13979 14341 17713 16019 14688>,
			<12826 13955 14286 17941 16218 15784>,
			<11139 12023 14226 18326 17342 15777>,
			<9720 9729 13800 18796 17426 16653>,
			<8961 8954 11005 19800 21941 23287>,
			<8961 8954 11005 19800 21941 23287>,
			<8961 8954 11005 19800 21941 23287>;
	};

	qcom,pc-temp-y6-lut {
		qcom,lut-col-legend = <(-10) 0 10 25 40 50>;
		qcom,lut-row-legend = <10000 9800 9600 9400 9200 9000>,
			<8800 8600 8400 8200 8000 7800>,
			<7600 7400 7200 7000 6800 6600>,
			<6400 6200 6000 5800 5600 5400>,
			<5200 5000 4800 4600 4400 4200>,
			<4000 3800 3600 3400 3200 3000>,
			<2800 2600 2400 2200 2000 1800>,
			<1600 1400 1200 1000 900 800>,
			<700 600 500 400 300 200>,
			<100 0>;
		qcom,lut-data = <6140 5560 5288 5104 5048 5034>,
			<6156 5576 5299 5105 5049 5035>,
			<6166 5591 5308 5106 5050 5037>,
			<6171 5604 5314 5107 5051 5039>,
			<6172 5613 5317 5107 5052 5041>,
			<6171 5616 5318 5108 5053 5042>,
			<6161 5614 5316 5108 5053 5043>,
			<6142 5609 5312 5109 5054 5043>,
			<6129 5605 5308 5110 5055 5044>,
			<6117 5601 5304 5111 5057 5045>,
			<6110 5596 5303 5113 5059 5046>,
			<6109 5590 5303 5115 5061 5047>,
			<6108 5585 5303 5117 5063 5049>,
			<6104 5590 5305 5120 5066 5052>,
			<6086 5613 5310 5124 5068 5054>,
			<6061 5626 5314 5129 5071 5056>,
			<6025 5602 5316 5134 5074 5058>,
			<5979 5565 5317 5139 5078 5061>,
			<5956 5547 5313 5147 5084 5065>,
			<5947 5537 5297 5156 5091 5072>,
			<5940 5527 5281 5159 5094 5074>,
			<5930 5514 5265 5143 5087 5070>,
			<5921 5502 5251 5120 5077 5064>,
			<5919 5494 5242 5107 5066 5055>,
			<5922 5489 5235 5098 5054 5042>,
			<5928 5485 5232 5095 5050 5038>,
			<5941 5478 5231 5096 5050 5038>,
			<5967 5473 5230 5097 5051 5039>,
			<5993 5477 5228 5099 5053 5041>,
			<6019 5498 5225 5101 5056 5044>,
			<6047 5524 5224 5103 5059 5047>,
			<6078 5554 5224 5106 5063 5051>,
			<6112 5588 5225 5109 5067 5054>,
			<6146 5627 5231 5110 5068 5056>,
			<6181 5672 5249 5112 5068 5057>,
			<6215 5721 5268 5113 5068 5057>,
			<6248 5772 5290 5111 5064 5052>,
			<6281 5828 5316 5110 5060 5048>,
			<6310 5888 5345 5110 5059 5048>,
			<6332 5954 5379 5112 5058 5049>,
			<6353 6017 5413 5115 5059 5051>,
			<6378 6077 5446 5122 5062 5054>,
			<6408 6132 5482 5126 5060 5052>,
			<6448 6179 5521 5127 5049 5038>,
			<6506 6244 5571 5132 5050 5038>,
			<6591 6255 5587 5127 5055 5048>,
			<6601 6324 5641 5136 5066 5061>,
			<6695 6406 5711 5149 5080 5074>,
			<6842 6511 5808 5163 5091 5085>,
			<7119 6670 5940 5177 5097 5086>,
			<8040 7039 6122 5164 5070 5056>,
			<10326 8512 6396 5166 5064 5054>,
			<16759 14740 6853 5194 5069 5059>,
			<40661 56844 8992 5241 5084 5074>,
			<40661 56844 8992 5241 5084 5074>,
			<40661 56844 8992 5241 5084 5074>;
	};

};
